AUTOSAR XML (schema 4-2-2)
package /ComponentTypes
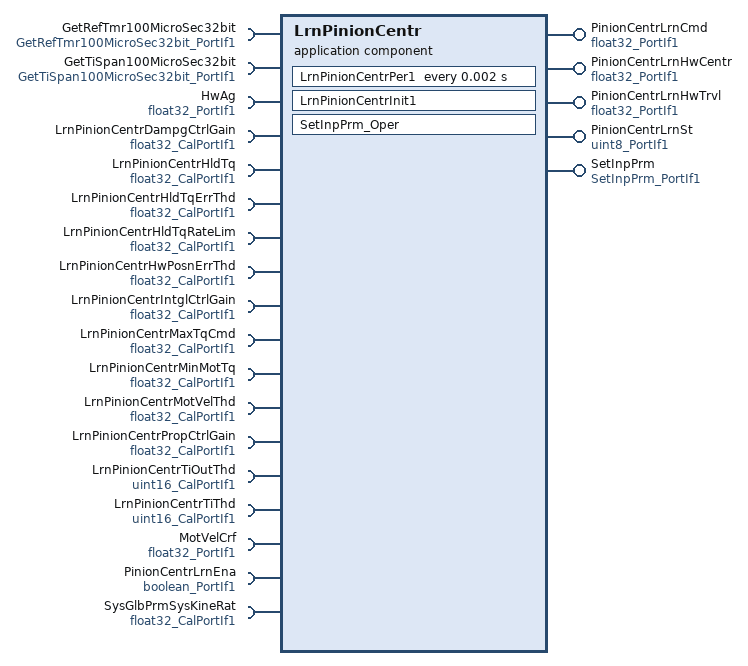
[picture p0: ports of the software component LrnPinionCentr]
  application sw component type LrnPinionCentr
    5 x provide port:
      PinionCentrLrnCmd: nonqueued-sender-com-spec{data-element=Val, init-value=0}, provided-interface=float32_PortIf1
      PinionCentrLrnHwCentr: nonqueued-sender-com-spec{data-element=Val, init-value=0}, provided-interface=float32_PortIf1
      PinionCentrLrnHwTrvl: nonqueued-sender-com-spec{data-element=Val, init-value=0}, provided-interface=float32_PortIf1
      PinionCentrLrnSt: nonqueued-sender-com-spec{data-element=Val, init-value=0}, provided-interface=uint8_PortIf1
      SetInpPrm: server-com-spec{operation=Oper, queue-length=1}, provided-interface=SetInpPrm_PortIf1
    18 x require port:
      GetRefTmr100MicroSec32bit: client-com-spec=Oper, required-interface=GetRefTmr100MicroSec32bit_PortIf1
      GetTiSpan100MicroSec32bit: client-com-spec=Oper, required-interface=GetTiSpan100MicroSec32bit_PortIf1
      HwAg: nonqueued-receiver-com-spec{data-element=Val, filter=data-filter-type=ALWAYS, init-value=0}, required-interface=float32_PortIf1
      LrnPinionCentrDampgCtrlGain: parameter-require-com-spec{init-value=0, parameter=Val}, required-interface=float32_CalPortIf1
      LrnPinionCentrHldTq: parameter-require-com-spec{init-value=0, parameter=Val}, required-interface=float32_CalPortIf1
      LrnPinionCentrHldTqErrThd: parameter-require-com-spec{init-value=1, parameter=Val}, required-interface=float32_CalPortIf1
      LrnPinionCentrHldTqRateLim: parameter-require-com-spec{init-value=100, parameter=Val}, required-interface=float32_CalPortIf1
      LrnPinionCentrHwPosnErrThd: parameter-require-com-spec{init-value=100, parameter=Val}, required-interface=float32_CalPortIf1
      LrnPinionCentrIntglCtrlGain: parameter-require-com-spec{init-value=0, parameter=Val}, required-interface=float32_CalPortIf1
      LrnPinionCentrMaxTqCmd: parameter-require-com-spec{init-value=0, parameter=Val}, required-interface=float32_CalPortIf1
      LrnPinionCentrMinMotTq: parameter-require-com-spec{init-value=0.01, parameter=Val}, required-interface=float32_CalPortIf1
      LrnPinionCentrMotVelThd: parameter-require-com-spec{init-value=500, parameter=Val}, required-interface=float32_CalPortIf1
      LrnPinionCentrPropCtrlGain: parameter-require-com-spec{init-value=5, parameter=Val}, required-interface=float32_CalPortIf1
      LrnPinionCentrTiOutThd: parameter-require-com-spec{init-value=200, parameter=Val}, required-interface=uint16_CalPortIf1
      LrnPinionCentrTiThd: parameter-require-com-spec{init-value=100, parameter=Val}, required-interface=uint16_CalPortIf1
      MotVelCrf: nonqueued-receiver-com-spec{data-element=Val, filter=data-filter-type=ALWAYS, init-value=0}, required-interface=float32_PortIf1
      PinionCentrLrnEna: nonqueued-receiver-com-spec{data-element=Logl, filter=data-filter-type=ALWAYS, init-value=0}, required-interface=boolean_PortIf1
      SysGlbPrmSysKineRat: parameter-require-com-spec{init-value=22, parameter=Val}, required-interface=float32_CalPortIf1
    behavior LrnPinionCentr_InternalBehavior
      ar-typed-per-instance-memorys:
        35 x data, all with sw-calibration-access=READ-ONLY:
          dLrnPinionCentrHwPosnCmd: type=float32
          MaxHwPosnPrev: type=float32
          MinHwPosnPrev: type=float32
          PinionCentrLrnEnaPrev: type=boolean
          PinionCentrLrnHwCentrPrev: type=float32
          PinionCentrLrnHwTrvlPrev: type=float32
          StCtrl1PosnErrRateLim: type=float32
          StCtrl1RateLimdPosnErrLpFil: type=FilLpRec1
          StCtrl1TmrARefTi: type=uint32
          StCtrl1TmrBRefTi: type=uint32
          StCtrl2RateLimdTqErrLpFil: type=FilLpRec1
          StCtrl2TmrARefTi: type=uint32
          StCtrl2TmrBRefTi: type=uint32
          StCtrl2TqErrRateLim: type=float32
          StCtrl3PosnErrRateLim: type=float32
          StCtrl3RateLimdPosnErrLpFil: type=FilLpRec1
          StCtrl3RateLimdTqErrLpFil: type=FilLpRec1
          StCtrl3TmrARefTi: type=uint32
          StCtrl3TmrBRefTi: type=uint32
          StCtrl3TqErrRateLim: type=float32
          StCtrl4RateLimdTqErrLpFil: type=FilLpRec1
          StCtrl4TmrARefTi: type=uint32
          StCtrl4TmrBRefTi: type=uint32
          StCtrl4TqErrRateLim: type=float32
          StCtrl5IntglEnaOutpPrev: type=float32
          StCtrl5PosnErrRateLim: type=float32
          StCtrl5RateLimdPosnErrLpFil: type=FilLpRec1
          StCtrl5RateLimdTqErrLpFil: type=FilLpRec1
          StCtrl5TmrARefTi: type=uint32
          StCtrl5TmrBRefTi: type=uint32
          StCtrl5TqErrRateLim: type=float32
          StEstimdPrev: type=uint8
          TarHwAg: type=float32
          TarMotVel: type=float32
          TqCmdEstimdPrev: type=float32
      init event LrnPinionCentr_InitEvent: start-on-event=LrnPinionCentrInit1
      timing event TMT_LrnPinionCentrPer1: start-on-event=LrnPinionCentrPer1, period=0.002
      operation invoked event OIT_SetInpPrm_Oper_SetInpPrm_Oper: start-on-event=SetInpPrm_Oper, operation=SetInpPrm.Oper
      explicit-inter-runnable-variables:
        data TarA: type=float32, init-value=0
        data TarVel: type=float32, init-value=0
      port-api-options:
        enable-take-address=false, error-handling=NO-TRANSFORMER-ERROR-HANDLING, indirect-api=false, port=LrnPinionCentrMinMotTq
        enable-take-address=false, error-handling=NO-TRANSFORMER-ERROR-HANDLING, indirect-api=false, port=LrnPinionCentrMotVelThd
        enable-take-address=false, error-handling=NO-TRANSFORMER-ERROR-HANDLING, indirect-api=false, port=LrnPinionCentrPropCtrlGain
        enable-take-address=false, error-handling=NO-TRANSFORMER-ERROR-HANDLING, indirect-api=false, port=LrnPinionCentrTiOutThd
      runnable LrnPinionCentrInit1
        data-receive-point-by-arguments:
          access REC_HwAg_Val: accessed-variable=HwAg.Val
      runnable LrnPinionCentrPer1
        data-receive-point-by-arguments:
          access REC_HwAg_Val: accessed-variable=HwAg.Val
          access REC_MotVelCrf_Val: accessed-variable=MotVelCrf.Val
          access REC_PinionCentrLrnEna_Logl: accessed-variable=PinionCentrLrnEna.Logl
        data-send-points:
          4 x access:
            SEND_PinionCentrLrnCmd_Val: accessed-variable=PinionCentrLrnCmd.Val
            SEND_PinionCentrLrnHwCentr_Val: accessed-variable=PinionCentrLrnHwCentr.Val
            SEND_PinionCentrLrnHwTrvl_Val: accessed-variable=PinionCentrLrnHwTrvl.Val
            SEND_PinionCentrLrnSt_Val: accessed-variable=PinionCentrLrnSt.Val
        read-local-variables:
          access READ_TarA: accessed-variable=TarA
          access READ_TarVel: accessed-variable=TarVel
        sync call SC_GetRefTmr100MicroSec32bit_Oper: operation=GetRefTmr100MicroSec32bit.Oper, timeout=0
        sync call SC_GetTiSpan100MicroSec32bit_Oper: operation=GetTiSpan100MicroSec32bit.Oper, timeout=0
      runnable SetInpPrm_Oper
        written-local-variables:
          access WRITE_TarA: accessed-variable=TarA
          access WRITE_TarVel: accessed-variable=TarVel
  swc implementation LrnPinionCentr_Implementation: behavior=LrnPinionCentr_InternalBehavior
    code-descriptors:
      code Default: artifact-descriptors=autosar-engineering-object={short-label=Default, category=SWSRC}
